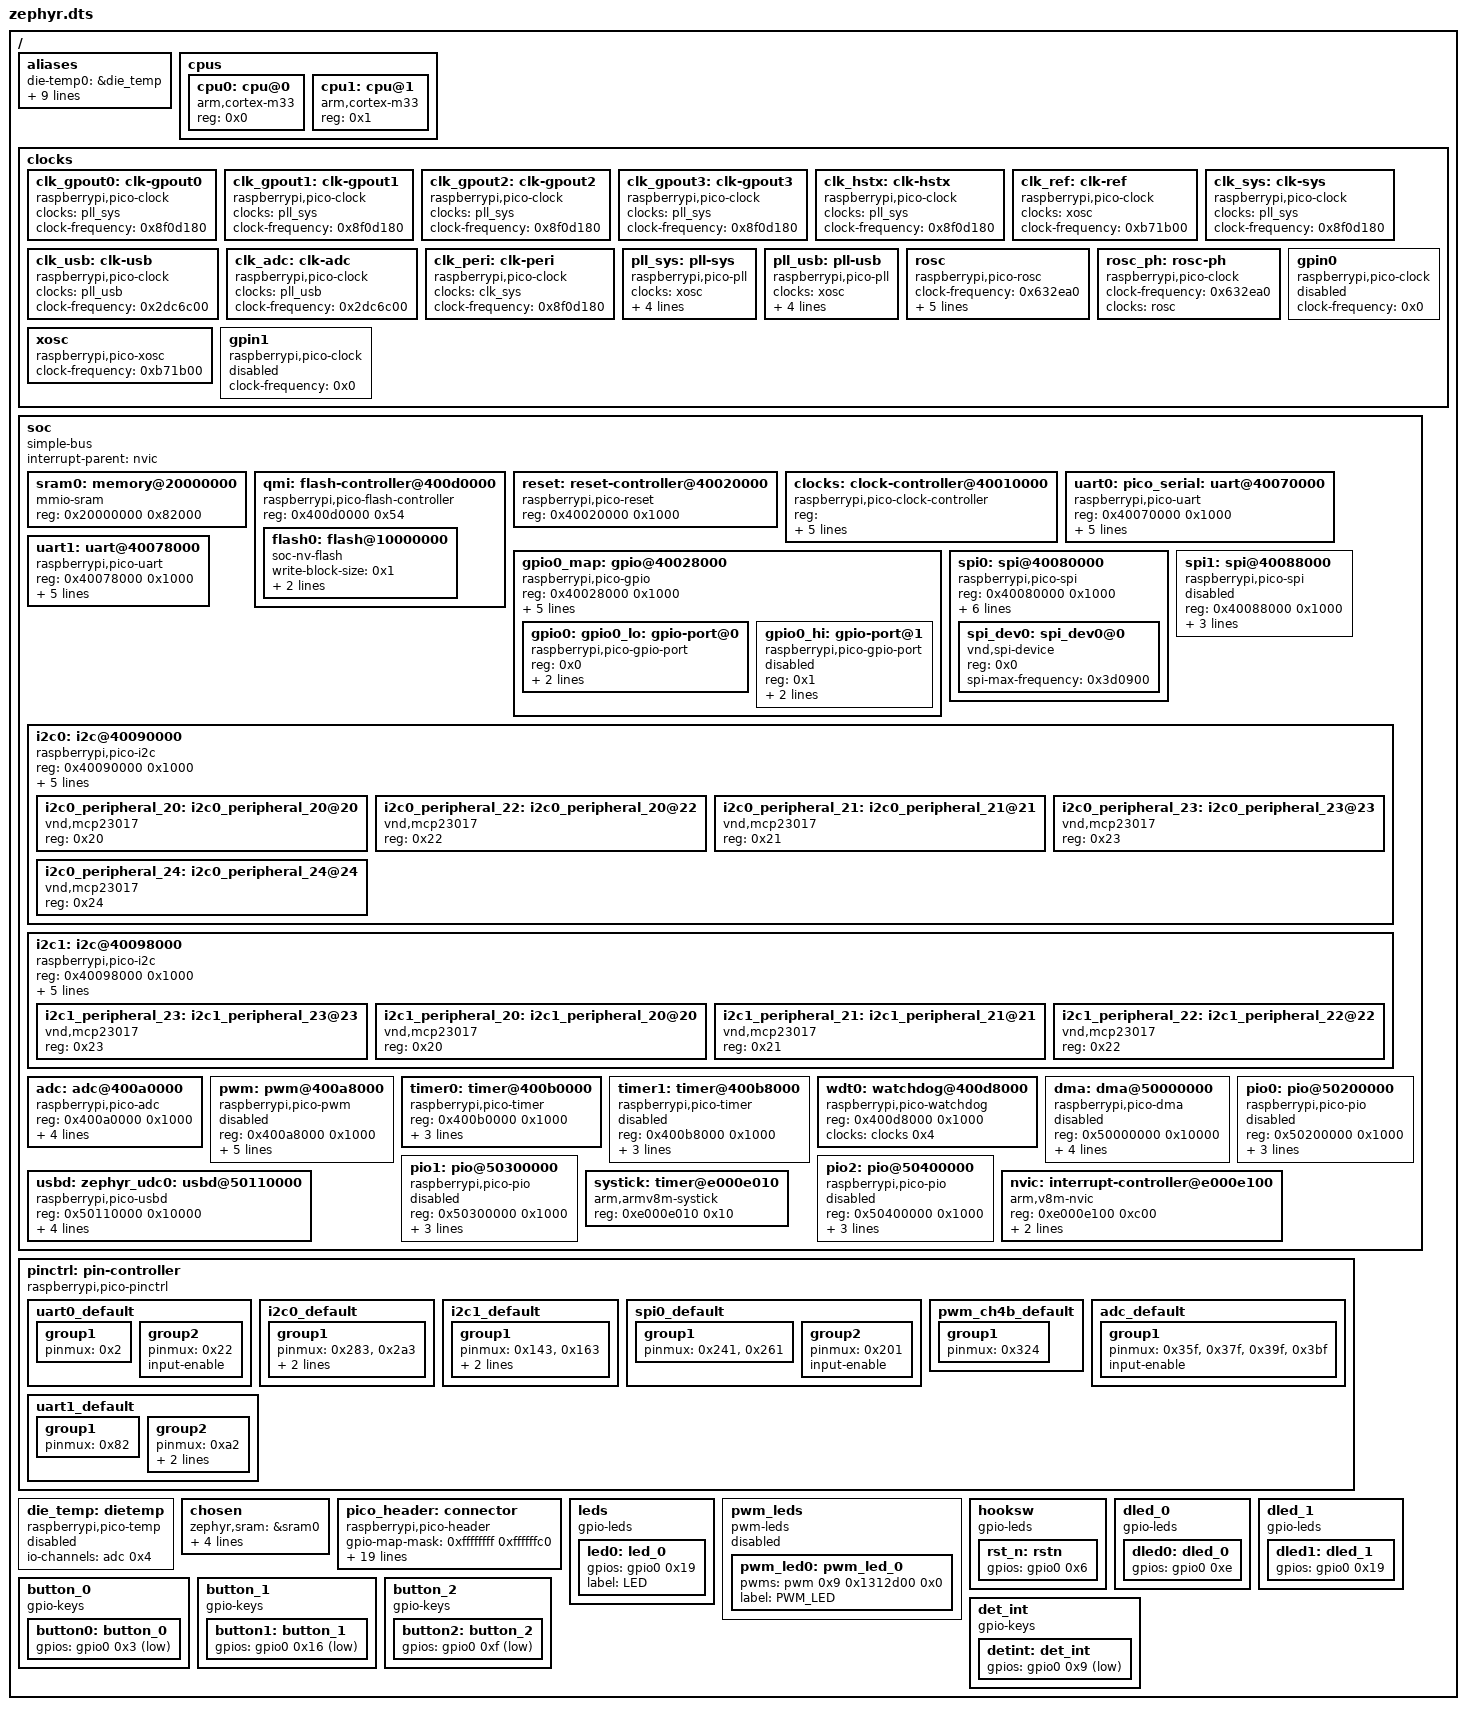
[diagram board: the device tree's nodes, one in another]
/dts-v1/;

/* node '/' defined in zephyr/dts/vendor/raspberrypi/rpi_pico/rp2350.dtsi:19 */
/ {
	#address-cells = < 0x1 >; /* in zephyr/dts/common/skeleton.dtsi:10 */
	#size-cells = < 0x1 >;    /* in zephyr/dts/common/skeleton.dtsi:11 */

	/* node '/aliases' defined in zephyr/dts/vendor/raspberrypi/rpi_pico/rp2350.dtsi:20 */
	aliases {
		die-temp0 = &die_temp; /* in zephyr/dts/vendor/raspberrypi/rpi_pico/rp2350.dtsi:21 */
		watchdog0 = &wdt0;     /* in zephyr/boards/raspberrypi/rpi_pico2/rpi_pico2.dtsi:24 */
		pwm-led0 = &pwm_led0;  /* in zephyr/boards/raspberrypi/common/rpi_pico-led.dtsi:30 */
		rstn = &rst_n;         /* in ../Documents/BLUELINE/blueline/code_blueline/boards/rpi_pico2_rp2350a_m33.overlay:183 */
		sw0 = &button0;        /* in ../Documents/BLUELINE/blueline/code_blueline/boards/rpi_pico2_rp2350a_m33.overlay:184 */
		sw1 = &button1;        /* in ../Documents/BLUELINE/blueline/code_blueline/boards/rpi_pico2_rp2350a_m33.overlay:185 */
		sw2 = &button2;        /* in ../Documents/BLUELINE/blueline/code_blueline/boards/rpi_pico2_rp2350a_m33.overlay:186 */
		detint = &detint;      /* in ../Documents/BLUELINE/blueline/code_blueline/boards/rpi_pico2_rp2350a_m33.overlay:187 */
		led0 = &dled0;         /* in ../Documents/BLUELINE/blueline/code_blueline/boards/rpi_pico2_rp2350a_m33.overlay:188 */
		led1 = &dled1;         /* in ../Documents/BLUELINE/blueline/code_blueline/boards/rpi_pico2_rp2350a_m33.overlay:189 */
	};

	/* node '/cpus' defined in zephyr/dts/vendor/raspberrypi/rpi_pico/rp2350.dtsi:24 */
	cpus {
		#address-cells = < 0x1 >; /* in zephyr/dts/vendor/raspberrypi/rpi_pico/rp2350.dtsi:25 */
		#size-cells = < 0x0 >;    /* in zephyr/dts/vendor/raspberrypi/rpi_pico/rp2350.dtsi:26 */

		/* node '/cpus/cpu@0' defined in zephyr/dts/vendor/raspberrypi/rpi_pico/rp2350.dtsi:33 */
		cpu0: cpu@0 {
			reg = < 0x0 >;                 /* in zephyr/dts/vendor/raspberrypi/rpi_pico/rp2350.dtsi:34 */
			compatible = "arm,cortex-m33"; /* in zephyr/dts/arm/raspberrypi/rpi_pico/m33.dtsi:13 */
		};

		/* node '/cpus/cpu@1' defined in zephyr/dts/vendor/raspberrypi/rpi_pico/rp2350.dtsi:37 */
		cpu1: cpu@1 {
			reg = < 0x1 >;                 /* in zephyr/dts/vendor/raspberrypi/rpi_pico/rp2350.dtsi:38 */
			compatible = "arm,cortex-m33"; /* in zephyr/dts/arm/raspberrypi/rpi_pico/m33.dtsi:17 */
		};
	};

	/* node '/clocks' defined in zephyr/dts/vendor/raspberrypi/rpi_pico/rp2350.dtsi:42 */
	clocks {

		/* node '/clocks/clk-gpout0' defined in zephyr/dts/vendor/raspberrypi/rpi_pico/rp2350.dtsi:43 */
		clk_gpout0: clk-gpout0 {
			compatible = "raspberrypi,pico-clock"; /* in zephyr/dts/vendor/raspberrypi/rpi_pico/rp2350.dtsi:44 */
			clocks = < &pll_sys >;                 /* in zephyr/dts/vendor/raspberrypi/rpi_pico/rp2350.dtsi:45 */
			clock-names = "pll_sys";               /* in zephyr/dts/vendor/raspberrypi/rpi_pico/rp2350.dtsi:46 */
			clock-frequency = < 0x8f0d180 >;       /* in zephyr/dts/vendor/raspberrypi/rpi_pico/rp2350.dtsi:47 */
			#clock-cells = < 0x0 >;                /* in zephyr/dts/vendor/raspberrypi/rpi_pico/rp2350.dtsi:48 */
			#address-cells = < 0x0 >;              /* in zephyr/dts/vendor/raspberrypi/rpi_pico/rp2350.dtsi:49 */
			phandle = < 0x7 >;                     /* in zephyr/dts/vendor/raspberrypi/rpi_pico/rp2350.dtsi:223 */
		};

		/* node '/clocks/clk-gpout1' defined in zephyr/dts/vendor/raspberrypi/rpi_pico/rp2350.dtsi:52 */
		clk_gpout1: clk-gpout1 {
			compatible = "raspberrypi,pico-clock"; /* in zephyr/dts/vendor/raspberrypi/rpi_pico/rp2350.dtsi:53 */
			clocks = < &pll_sys >;                 /* in zephyr/dts/vendor/raspberrypi/rpi_pico/rp2350.dtsi:54 */
			clock-names = "pll_sys";               /* in zephyr/dts/vendor/raspberrypi/rpi_pico/rp2350.dtsi:55 */
			clock-frequency = < 0x8f0d180 >;       /* in zephyr/dts/vendor/raspberrypi/rpi_pico/rp2350.dtsi:56 */
			#clock-cells = < 0x0 >;                /* in zephyr/dts/vendor/raspberrypi/rpi_pico/rp2350.dtsi:57 */
			phandle = < 0x8 >;                     /* in zephyr/dts/vendor/raspberrypi/rpi_pico/rp2350.dtsi:223 */
		};

		/* node '/clocks/clk-gpout2' defined in zephyr/dts/vendor/raspberrypi/rpi_pico/rp2350.dtsi:60 */
		clk_gpout2: clk-gpout2 {
			compatible = "raspberrypi,pico-clock"; /* in zephyr/dts/vendor/raspberrypi/rpi_pico/rp2350.dtsi:61 */
			clocks = < &pll_sys >;                 /* in zephyr/dts/vendor/raspberrypi/rpi_pico/rp2350.dtsi:62 */
			clock-names = "pll_sys";               /* in zephyr/dts/vendor/raspberrypi/rpi_pico/rp2350.dtsi:63 */
			clock-frequency = < 0x8f0d180 >;       /* in zephyr/dts/vendor/raspberrypi/rpi_pico/rp2350.dtsi:64 */
			#clock-cells = < 0x0 >;                /* in zephyr/dts/vendor/raspberrypi/rpi_pico/rp2350.dtsi:65 */
			phandle = < 0x9 >;                     /* in zephyr/dts/vendor/raspberrypi/rpi_pico/rp2350.dtsi:223 */
		};

		/* node '/clocks/clk-gpout3' defined in zephyr/dts/vendor/raspberrypi/rpi_pico/rp2350.dtsi:68 */
		clk_gpout3: clk-gpout3 {
			compatible = "raspberrypi,pico-clock"; /* in zephyr/dts/vendor/raspberrypi/rpi_pico/rp2350.dtsi:69 */
			clocks = < &pll_sys >;                 /* in zephyr/dts/vendor/raspberrypi/rpi_pico/rp2350.dtsi:70 */
			clock-names = "pll_sys";               /* in zephyr/dts/vendor/raspberrypi/rpi_pico/rp2350.dtsi:71 */
			clock-frequency = < 0x8f0d180 >;       /* in zephyr/dts/vendor/raspberrypi/rpi_pico/rp2350.dtsi:72 */
			#clock-cells = < 0x0 >;                /* in zephyr/dts/vendor/raspberrypi/rpi_pico/rp2350.dtsi:73 */
			phandle = < 0xa >;                     /* in zephyr/dts/vendor/raspberrypi/rpi_pico/rp2350.dtsi:223 */
		};

		/* node '/clocks/clk-hstx' defined in zephyr/dts/vendor/raspberrypi/rpi_pico/rp2350.dtsi:76 */
		clk_hstx: clk-hstx {
			compatible = "raspberrypi,pico-clock"; /* in zephyr/dts/vendor/raspberrypi/rpi_pico/rp2350.dtsi:77 */
			clocks = < &pll_sys >;                 /* in zephyr/dts/vendor/raspberrypi/rpi_pico/rp2350.dtsi:78 */
			clock-names = "pll_sys";               /* in zephyr/dts/vendor/raspberrypi/rpi_pico/rp2350.dtsi:79 */
			clock-frequency = < 0x8f0d180 >;       /* in zephyr/dts/vendor/raspberrypi/rpi_pico/rp2350.dtsi:80 */
			#clock-cells = < 0x0 >;                /* in zephyr/dts/vendor/raspberrypi/rpi_pico/rp2350.dtsi:81 */
			phandle = < 0xb >;                     /* in zephyr/dts/vendor/raspberrypi/rpi_pico/rp2350.dtsi:223 */
		};

		/* node '/clocks/clk-ref' defined in zephyr/dts/vendor/raspberrypi/rpi_pico/rp2350.dtsi:84 */
		clk_ref: clk-ref {
			compatible = "raspberrypi,pico-clock"; /* in zephyr/dts/vendor/raspberrypi/rpi_pico/rp2350.dtsi:85 */
			clocks = < &xosc >;                    /* in zephyr/dts/vendor/raspberrypi/rpi_pico/rp2350.dtsi:86 */
			clock-names = "xosc";                  /* in zephyr/dts/vendor/raspberrypi/rpi_pico/rp2350.dtsi:87 */
			clock-frequency = < 0xb71b00 >;        /* in zephyr/dts/vendor/raspberrypi/rpi_pico/rp2350.dtsi:88 */
			#clock-cells = < 0x0 >;                /* in zephyr/dts/vendor/raspberrypi/rpi_pico/rp2350.dtsi:89 */
			phandle = < 0xc >;                     /* in zephyr/dts/vendor/raspberrypi/rpi_pico/rp2350.dtsi:223 */
		};

		/* node '/clocks/clk-sys' defined in zephyr/dts/vendor/raspberrypi/rpi_pico/rp2350.dtsi:92 */
		clk_sys: clk-sys {
			compatible = "raspberrypi,pico-clock"; /* in zephyr/dts/vendor/raspberrypi/rpi_pico/rp2350.dtsi:93 */
			clocks = < &pll_sys >;                 /* in zephyr/dts/vendor/raspberrypi/rpi_pico/rp2350.dtsi:94 */
			clock-names = "pll_sys";               /* in zephyr/dts/vendor/raspberrypi/rpi_pico/rp2350.dtsi:95 */
			clock-frequency = < 0x8f0d180 >;       /* in zephyr/dts/vendor/raspberrypi/rpi_pico/rp2350.dtsi:96 */
			#clock-cells = < 0x0 >;                /* in zephyr/dts/vendor/raspberrypi/rpi_pico/rp2350.dtsi:97 */
			phandle = < 0x4 >;                     /* in zephyr/dts/vendor/raspberrypi/rpi_pico/rp2350.dtsi:118 */
		};

		/* node '/clocks/clk-usb' defined in zephyr/dts/vendor/raspberrypi/rpi_pico/rp2350.dtsi:100 */
		clk_usb: clk-usb {
			compatible = "raspberrypi,pico-clock"; /* in zephyr/dts/vendor/raspberrypi/rpi_pico/rp2350.dtsi:101 */
			clocks = < &pll_usb >;                 /* in zephyr/dts/vendor/raspberrypi/rpi_pico/rp2350.dtsi:102 */
			clock-names = "pll_usb";               /* in zephyr/dts/vendor/raspberrypi/rpi_pico/rp2350.dtsi:103 */
			clock-frequency = < 0x2dc6c00 >;       /* in zephyr/dts/vendor/raspberrypi/rpi_pico/rp2350.dtsi:104 */
			#clock-cells = < 0x0 >;                /* in zephyr/dts/vendor/raspberrypi/rpi_pico/rp2350.dtsi:105 */
			phandle = < 0xe >;                     /* in zephyr/dts/vendor/raspberrypi/rpi_pico/rp2350.dtsi:223 */
		};

		/* node '/clocks/clk-adc' defined in zephyr/dts/vendor/raspberrypi/rpi_pico/rp2350.dtsi:108 */
		clk_adc: clk-adc {
			compatible = "raspberrypi,pico-clock"; /* in zephyr/dts/vendor/raspberrypi/rpi_pico/rp2350.dtsi:109 */
			clocks = < &pll_usb >;                 /* in zephyr/dts/vendor/raspberrypi/rpi_pico/rp2350.dtsi:110 */
			clock-names = "pll_usb";               /* in zephyr/dts/vendor/raspberrypi/rpi_pico/rp2350.dtsi:111 */
			clock-frequency = < 0x2dc6c00 >;       /* in zephyr/dts/vendor/raspberrypi/rpi_pico/rp2350.dtsi:112 */
			#clock-cells = < 0x0 >;                /* in zephyr/dts/vendor/raspberrypi/rpi_pico/rp2350.dtsi:113 */
			phandle = < 0xf >;                     /* in zephyr/dts/vendor/raspberrypi/rpi_pico/rp2350.dtsi:223 */
		};

		/* node '/clocks/clk-peri' defined in zephyr/dts/vendor/raspberrypi/rpi_pico/rp2350.dtsi:116 */
		clk_peri: clk-peri {
			compatible = "raspberrypi,pico-clock"; /* in zephyr/dts/vendor/raspberrypi/rpi_pico/rp2350.dtsi:117 */
			clocks = < &clk_sys >;                 /* in zephyr/dts/vendor/raspberrypi/rpi_pico/rp2350.dtsi:118 */
			clock-names = "clk_sys";               /* in zephyr/dts/vendor/raspberrypi/rpi_pico/rp2350.dtsi:119 */
			clock-frequency = < 0x8f0d180 >;       /* in zephyr/dts/vendor/raspberrypi/rpi_pico/rp2350.dtsi:120 */
			#clock-cells = < 0x0 >;                /* in zephyr/dts/vendor/raspberrypi/rpi_pico/rp2350.dtsi:121 */
			phandle = < 0xd >;                     /* in zephyr/dts/vendor/raspberrypi/rpi_pico/rp2350.dtsi:223 */
		};

		/* node '/clocks/pll-sys' defined in zephyr/dts/vendor/raspberrypi/rpi_pico/rp2350.dtsi:124 */
		pll_sys: pll-sys {
			compatible = "raspberrypi,pico-pll"; /* in zephyr/dts/vendor/raspberrypi/rpi_pico/rp2350.dtsi:125 */
			clocks = < &xosc >;                  /* in zephyr/dts/vendor/raspberrypi/rpi_pico/rp2350.dtsi:126 */
			clock-names = "xosc";                /* in zephyr/dts/vendor/raspberrypi/rpi_pico/rp2350.dtsi:127 */
			clock-div = < 0x1 >;                 /* in zephyr/dts/vendor/raspberrypi/rpi_pico/rp2350.dtsi:128 */
			fb-div = < 0x7d >;                   /* in zephyr/dts/vendor/raspberrypi/rpi_pico/rp2350.dtsi:129 */
			post-div1 = < 0x5 >;                 /* in zephyr/dts/vendor/raspberrypi/rpi_pico/rp2350.dtsi:130 */
			post-div2 = < 0x2 >;                 /* in zephyr/dts/vendor/raspberrypi/rpi_pico/rp2350.dtsi:131 */
			#clock-cells = < 0x0 >;              /* in zephyr/dts/vendor/raspberrypi/rpi_pico/rp2350.dtsi:132 */
			phandle = < 0x1 >;                   /* in zephyr/dts/vendor/raspberrypi/rpi_pico/rp2350.dtsi:45 */
		};

		/* node '/clocks/pll-usb' defined in zephyr/dts/vendor/raspberrypi/rpi_pico/rp2350.dtsi:135 */
		pll_usb: pll-usb {
			compatible = "raspberrypi,pico-pll"; /* in zephyr/dts/vendor/raspberrypi/rpi_pico/rp2350.dtsi:136 */
			clocks = < &xosc >;                  /* in zephyr/dts/vendor/raspberrypi/rpi_pico/rp2350.dtsi:137 */
			clock-names = "xosc";                /* in zephyr/dts/vendor/raspberrypi/rpi_pico/rp2350.dtsi:138 */
			clock-div = < 0x1 >;                 /* in zephyr/dts/vendor/raspberrypi/rpi_pico/rp2350.dtsi:139 */
			fb-div = < 0x64 >;                   /* in zephyr/dts/vendor/raspberrypi/rpi_pico/rp2350.dtsi:140 */
			post-div1 = < 0x5 >;                 /* in zephyr/dts/vendor/raspberrypi/rpi_pico/rp2350.dtsi:141 */
			post-div2 = < 0x5 >;                 /* in zephyr/dts/vendor/raspberrypi/rpi_pico/rp2350.dtsi:142 */
			#clock-cells = < 0x0 >;              /* in zephyr/dts/vendor/raspberrypi/rpi_pico/rp2350.dtsi:143 */
			phandle = < 0x3 >;                   /* in zephyr/dts/vendor/raspberrypi/rpi_pico/rp2350.dtsi:102 */
		};

		/* node '/clocks/rosc' defined in zephyr/dts/vendor/raspberrypi/rpi_pico/rp2350.dtsi:146 */
		rosc: rosc {
			compatible = "raspberrypi,pico-rosc"; /* in zephyr/dts/vendor/raspberrypi/rpi_pico/rp2350.dtsi:147 */
			clock-frequency = < 0x632ea0 >;       /* in zephyr/dts/vendor/raspberrypi/rpi_pico/rp2350.dtsi:148 */
			range = < 0xaa0 >;                    /* in zephyr/dts/vendor/raspberrypi/rpi_pico/rp2350.dtsi:149 */
			stage-drive-strength = < 0x0 >,
			                       < 0x0 >,
			                       < 0x0 >,
			                       < 0x0 >,
			                       < 0x0 >,
			                       < 0x0 >,
			                       < 0x0 >,
			                       < 0x0 >;       /* in zephyr/dts/vendor/raspberrypi/rpi_pico/rp2350.dtsi:150 */
			clock-div = < 0x10 >;                 /* in zephyr/dts/vendor/raspberrypi/rpi_pico/rp2350.dtsi:151 */
			phase = < 0x0 >;                      /* in zephyr/dts/vendor/raspberrypi/rpi_pico/rp2350.dtsi:152 */
			#clock-cells = < 0x0 >;               /* in zephyr/dts/vendor/raspberrypi/rpi_pico/rp2350.dtsi:153 */
			phandle = < 0x5 >;                    /* in zephyr/dts/vendor/raspberrypi/rpi_pico/rp2350.dtsi:159 */
		};

		/* node '/clocks/rosc-ph' defined in zephyr/dts/vendor/raspberrypi/rpi_pico/rp2350.dtsi:156 */
		rosc_ph: rosc-ph {
			compatible = "raspberrypi,pico-clock"; /* in zephyr/dts/vendor/raspberrypi/rpi_pico/rp2350.dtsi:157 */
			clock-frequency = < 0x632ea0 >;        /* in zephyr/dts/vendor/raspberrypi/rpi_pico/rp2350.dtsi:158 */
			clocks = < &rosc >;                    /* in zephyr/dts/vendor/raspberrypi/rpi_pico/rp2350.dtsi:159 */
			clock-names = "rosc";                  /* in zephyr/dts/vendor/raspberrypi/rpi_pico/rp2350.dtsi:160 */
			#clock-cells = < 0x0 >;                /* in zephyr/dts/vendor/raspberrypi/rpi_pico/rp2350.dtsi:161 */
			phandle = < 0x10 >;                    /* in zephyr/dts/vendor/raspberrypi/rpi_pico/rp2350.dtsi:223 */
		};

		/* node '/clocks/xosc' defined in zephyr/dts/vendor/raspberrypi/rpi_pico/rp2350.dtsi:164 */
		xosc: xosc {
			compatible = "raspberrypi,pico-xosc"; /* in zephyr/dts/vendor/raspberrypi/rpi_pico/rp2350.dtsi:165 */
			clock-frequency = < 0xb71b00 >;       /* in zephyr/dts/vendor/raspberrypi/rpi_pico/rp2350.dtsi:166 */
			#clock-cells = < 0x0 >;               /* in zephyr/dts/vendor/raspberrypi/rpi_pico/rp2350.dtsi:167 */
			phandle = < 0x2 >;                    /* in zephyr/dts/vendor/raspberrypi/rpi_pico/rp2350.dtsi:86 */
		};

		/* node '/clocks/gpin0' defined in zephyr/dts/vendor/raspberrypi/rpi_pico/rp2350.dtsi:170 */
		gpin0: gpin0 {
			compatible = "raspberrypi,pico-clock"; /* in zephyr/dts/vendor/raspberrypi/rpi_pico/rp2350.dtsi:171 */
			status = "disabled";                   /* in zephyr/dts/vendor/raspberrypi/rpi_pico/rp2350.dtsi:172 */
			clock-frequency = < 0x0 >;             /* in zephyr/dts/vendor/raspberrypi/rpi_pico/rp2350.dtsi:173 */
			#clock-cells = < 0x0 >;                /* in zephyr/dts/vendor/raspberrypi/rpi_pico/rp2350.dtsi:174 */
			phandle = < 0x11 >;                    /* in zephyr/dts/vendor/raspberrypi/rpi_pico/rp2350.dtsi:223 */
		};

		/* node '/clocks/gpin1' defined in zephyr/dts/vendor/raspberrypi/rpi_pico/rp2350.dtsi:177 */
		gpin1: gpin1 {
			compatible = "raspberrypi,pico-clock"; /* in zephyr/dts/vendor/raspberrypi/rpi_pico/rp2350.dtsi:178 */
			status = "disabled";                   /* in zephyr/dts/vendor/raspberrypi/rpi_pico/rp2350.dtsi:179 */
			clock-frequency = < 0x0 >;             /* in zephyr/dts/vendor/raspberrypi/rpi_pico/rp2350.dtsi:180 */
			#clock-cells = < 0x0 >;                /* in zephyr/dts/vendor/raspberrypi/rpi_pico/rp2350.dtsi:181 */
			phandle = < 0x12 >;                    /* in zephyr/dts/vendor/raspberrypi/rpi_pico/rp2350.dtsi:223 */
		};
	};

	/* node '/soc' defined in zephyr/dts/vendor/raspberrypi/rpi_pico/rp2350.dtsi:185 */
	soc {
		#address-cells = < 0x1 >;     /* in zephyr/dts/arm/armv8-m.dtsi:7 */
		#size-cells = < 0x1 >;        /* in zephyr/dts/arm/armv8-m.dtsi:8 */
		compatible = "simple-bus";    /* in zephyr/dts/arm/armv8-m.dtsi:9 */
		interrupt-parent = < &nvic >; /* in zephyr/dts/arm/armv8-m.dtsi:10 */
		ranges;                       /* in zephyr/dts/arm/armv8-m.dtsi:11 */

		/* node '/soc/memory@20000000' defined in zephyr/dts/vendor/raspberrypi/rpi_pico/rp2350.dtsi:188 */
		sram0: memory@20000000 {
			compatible = "mmio-sram";     /* in zephyr/dts/vendor/raspberrypi/rpi_pico/rp2350.dtsi:189 */
			reg = < 0x20000000 0x82000 >; /* in zephyr/dts/vendor/raspberrypi/rpi_pico/rp2350.dtsi:190 */
		};

		/* node '/soc/flash-controller@400d0000' defined in zephyr/dts/vendor/raspberrypi/rpi_pico/rp2350.dtsi:193 */
		qmi: flash-controller@400d0000 {
			compatible = "raspberrypi,pico-flash-controller"; /* in zephyr/dts/vendor/raspberrypi/rpi_pico/rp2350.dtsi:194 */
			reg = < 0x400d0000 0x54 >;                        /* in zephyr/dts/vendor/raspberrypi/rpi_pico/rp2350.dtsi:195 */
			#address-cells = < 0x1 >;                         /* in zephyr/dts/vendor/raspberrypi/rpi_pico/rp2350.dtsi:197 */
			#size-cells = < 0x1 >;                            /* in zephyr/dts/vendor/raspberrypi/rpi_pico/rp2350.dtsi:198 */

			/* node '/soc/flash-controller@400d0000/flash@10000000' defined in zephyr/dts/vendor/raspberrypi/rpi_pico/rp2350.dtsi:200 */
			flash0: flash@10000000 {
				compatible = "soc-nv-flash";   /* in zephyr/dts/vendor/raspberrypi/rpi_pico/rp2350.dtsi:201 */
				write-block-size = < 0x1 >;    /* in zephyr/dts/vendor/raspberrypi/rpi_pico/rp2350.dtsi:202 */
				erase-block-size = < 0x1000 >; /* in zephyr/dts/vendor/raspberrypi/rpi_pico/rp2350.dtsi:203 */
				reg = < 0x10000000 0x400000 >; /* in zephyr/boards/raspberrypi/rpi_pico2/rpi_pico2.dtsi:62 */
			};
		};

		/* node '/soc/reset-controller@40020000' defined in zephyr/dts/vendor/raspberrypi/rpi_pico/rp2350.dtsi:207 */
		reset: reset-controller@40020000 {
			compatible = "raspberrypi,pico-reset"; /* in zephyr/dts/vendor/raspberrypi/rpi_pico/rp2350.dtsi:208 */
			reg = < 0x40020000 0x1000 >;           /* in zephyr/dts/vendor/raspberrypi/rpi_pico/rp2350.dtsi:209 */
			#reset-cells = < 0x1 >;                /* in zephyr/dts/vendor/raspberrypi/rpi_pico/rp2350.dtsi:210 */
			phandle = < 0x16 >;                    /* in zephyr/dts/vendor/raspberrypi/rpi_pico/rp2350.dtsi:271 */
		};

		/* node '/soc/clock-controller@40010000' defined in zephyr/dts/vendor/raspberrypi/rpi_pico/rp2350.dtsi:213 */
		clocks: clock-controller@40010000 {
			compatible = "raspberrypi,pico-clock-controller";                                          /* in zephyr/dts/vendor/raspberrypi/rpi_pico/rp2350.dtsi:214 */
			reg = < 0x40010000 0x1000 0x40048000 0x1000 0x40050000 0x1000 0x40058000 0x1000 0x400e8000
			        0x1000 >;                                                                          /* in zephyr/dts/vendor/raspberrypi/rpi_pico/rp2350.dtsi:215 */
			reg-names = "clocks",
			            "xosc",
			            "pll_sys",
			            "pll_usb",
			            "rosc";                                                                        /* in zephyr/dts/vendor/raspberrypi/rpi_pico/rp2350.dtsi:220 */
			#clock-cells = < 0x1 >;                                                                    /* in zephyr/dts/vendor/raspberrypi/rpi_pico/rp2350.dtsi:221 */
			status = "okay";                                                                           /* in zephyr/dts/vendor/raspberrypi/rpi_pico/rp2350.dtsi:222 */
			clocks = < &clk_gpout0 >,
			         < &clk_gpout1 >,
			         < &clk_gpout2 >,
			         < &clk_gpout3 >,
			         < &clk_hstx >,
			         < &clk_ref >,
			         < &clk_sys >,
			         < &clk_peri >,
			         < &clk_usb >,
			         < &clk_adc >,
			         < &pll_sys >,
			         < &pll_usb >,
			         < &xosc >,
			         < &rosc >,
			         < &rosc_ph >,
			         < &gpin0 >,
			         < &gpin1 >;                                                                       /* in zephyr/dts/vendor/raspberrypi/rpi_pico/rp2350.dtsi:223 */
			clock-names = "clk_gpout0",
			              "clk_gpout1",
			              "clk_gpout2",
			              "clk_gpout3",
			              "clk_hstx",
			              "clk_ref",
			              "clk_sys",
			              "clk_peri",
			              "clk_usb",
			              "clk_adc",
			              "pll_sys",
			              "pll_usb",
			              "xosc",
			              "rosc",
			              "rosc_ph",
			              "gpin0",
			              "gpin1";                                                                     /* in zephyr/dts/vendor/raspberrypi/rpi_pico/rp2350.dtsi:228 */
			phandle = < 0x15 >;                                                                        /* in zephyr/dts/vendor/raspberrypi/rpi_pico/rp2350.dtsi:270 */
		};

		/* node '/soc/gpio@40028000' defined in zephyr/dts/vendor/raspberrypi/rpi_pico/rp2350.dtsi:235 */
		gpio0_map: gpio@40028000 {
			compatible = "raspberrypi,pico-gpio";                             /* in zephyr/dts/vendor/raspberrypi/rpi_pico/rp2350.dtsi:236 */
			reg = < 0x40028000 0x1000 >;                                      /* in zephyr/dts/vendor/raspberrypi/rpi_pico/rp2350.dtsi:237 */
			interrupts = < 0x15 0x7 >;                                        /* in zephyr/dts/vendor/raspberrypi/rpi_pico/rp2350.dtsi:238 */
			gpio-map-mask = < 0xffffffe0 0xffffffc0 >;                        /* in zephyr/dts/vendor/raspberrypi/rpi_pico/rp2350.dtsi:240 */
			gpio-map-pass-thru = < 0x1f 0x3f >;                               /* in zephyr/dts/vendor/raspberrypi/rpi_pico/rp2350.dtsi:241 */
			gpio-map = < 0x0 0x0 &gpio0 0x0 0x0 0x20 0x0 &gpio0_hi 0x0 0x0 >; /* in zephyr/dts/vendor/raspberrypi/rpi_pico/rp2350.dtsi:242 */
			#gpio-cells = < 0x2 >;                                            /* in zephyr/dts/vendor/raspberrypi/rpi_pico/rp2350.dtsi:244 */
			#address-cells = < 0x1 >;                                         /* in zephyr/dts/vendor/raspberrypi/rpi_pico/rp2350.dtsi:245 */
			#size-cells = < 0x0 >;                                            /* in zephyr/dts/vendor/raspberrypi/rpi_pico/rp2350.dtsi:246 */

			/* node '/soc/gpio@40028000/gpio-port@0' defined in zephyr/dts/vendor/raspberrypi/rpi_pico/rp2350.dtsi:248 */
			gpio0: gpio0_lo: gpio-port@0 {
				compatible = "raspberrypi,pico-gpio-port"; /* in zephyr/dts/vendor/raspberrypi/rpi_pico/rp2350.dtsi:249 */
				reg = < 0x0 >;                             /* in zephyr/dts/vendor/raspberrypi/rpi_pico/rp2350.dtsi:250 */
				gpio-controller;                           /* in zephyr/dts/vendor/raspberrypi/rpi_pico/rp2350.dtsi:252 */
				#gpio-cells = < 0x2 >;                     /* in zephyr/dts/vendor/raspberrypi/rpi_pico/rp2350.dtsi:253 */
				ngpios = < 0x1e >;                         /* in zephyr/dts/vendor/raspberrypi/rpi_pico/rp2350a.dtsi:4 */
				status = "okay";                           /* in zephyr/boards/raspberrypi/rpi_pico2/rpi_pico2.dtsi:73 */
				phandle = < 0x13 >;                        /* in zephyr/dts/vendor/raspberrypi/rpi_pico/rp2350.dtsi:242 */
			};

			/* node '/soc/gpio@40028000/gpio-port@1' defined in zephyr/dts/vendor/raspberrypi/rpi_pico/rp2350.dtsi:257 */
			gpio0_hi: gpio-port@1 {
				compatible = "raspberrypi,pico-gpio-port"; /* in zephyr/dts/vendor/raspberrypi/rpi_pico/rp2350.dtsi:258 */
				reg = < 0x1 >;                             /* in zephyr/dts/vendor/raspberrypi/rpi_pico/rp2350.dtsi:259 */
				status = "disabled";                       /* in zephyr/dts/vendor/raspberrypi/rpi_pico/rp2350.dtsi:260 */
				gpio-controller;                           /* in zephyr/dts/vendor/raspberrypi/rpi_pico/rp2350.dtsi:261 */
				#gpio-cells = < 0x2 >;                     /* in zephyr/dts/vendor/raspberrypi/rpi_pico/rp2350.dtsi:262 */
				ngpios = < 0x20 >;                         /* in zephyr/dts/vendor/raspberrypi/rpi_pico/rp2350.dtsi:263 */
				phandle = < 0x14 >;                        /* in zephyr/dts/vendor/raspberrypi/rpi_pico/rp2350.dtsi:242 */
			};
		};

		/* node '/soc/uart@40070000' defined in zephyr/dts/vendor/raspberrypi/rpi_pico/rp2350.dtsi:267 */
		uart0: pico_serial: uart@40070000 {
			compatible = "raspberrypi,pico-uart",
			             "arm,pl011";             /* in zephyr/dts/vendor/raspberrypi/rpi_pico/rp2350.dtsi:268 */
			reg = < 0x40070000 0x1000 >;          /* in zephyr/dts/vendor/raspberrypi/rpi_pico/rp2350.dtsi:269 */
			clocks = < &clocks 0x6 >;             /* in zephyr/dts/vendor/raspberrypi/rpi_pico/rp2350.dtsi:270 */
			resets = < &reset 0x1a >;             /* in zephyr/dts/vendor/raspberrypi/rpi_pico/rp2350.dtsi:271 */
			interrupts = < 0x21 0x7 >;            /* in zephyr/dts/vendor/raspberrypi/rpi_pico/rp2350.dtsi:272 */
			interrupt-names = "uart0";            /* in zephyr/dts/vendor/raspberrypi/rpi_pico/rp2350.dtsi:273 */
			current-speed = < 0x1c200 >;          /* in zephyr/boards/raspberrypi/rpi_pico2/rpi_pico2.dtsi:66 */
			status = "okay";                      /* in zephyr/boards/raspberrypi/rpi_pico2/rpi_pico2.dtsi:67 */
			pinctrl-0 = < &uart0_default >;       /* in zephyr/boards/raspberrypi/rpi_pico2/rpi_pico2.dtsi:68 */
			pinctrl-names = "default";            /* in zephyr/boards/raspberrypi/rpi_pico2/rpi_pico2.dtsi:69 */
		};

		/* node '/soc/uart@40078000' defined in zephyr/dts/vendor/raspberrypi/rpi_pico/rp2350.dtsi:277 */
		uart1: uart@40078000 {
			compatible = "raspberrypi,pico-uart",
			             "arm,pl011";             /* in zephyr/dts/vendor/raspberrypi/rpi_pico/rp2350.dtsi:278 */
			reg = < 0x40078000 0x1000 >;          /* in zephyr/dts/vendor/raspberrypi/rpi_pico/rp2350.dtsi:279 */
			clocks = < &clocks 0x6 >;             /* in zephyr/dts/vendor/raspberrypi/rpi_pico/rp2350.dtsi:280 */
			resets = < &reset 0x1b >;             /* in zephyr/dts/vendor/raspberrypi/rpi_pico/rp2350.dtsi:281 */
			interrupts = < 0x22 0x7 >;            /* in zephyr/dts/vendor/raspberrypi/rpi_pico/rp2350.dtsi:282 */
			interrupt-names = "uart1";            /* in zephyr/dts/vendor/raspberrypi/rpi_pico/rp2350.dtsi:283 */
			status = "okay";                      /* in ../Documents/BLUELINE/blueline/code_blueline/boards/rpi_pico2_rp2350a_m33.overlay:46 */
			current-speed = < 0x1c200 >;          /* in ../Documents/BLUELINE/blueline/code_blueline/boards/rpi_pico2_rp2350a_m33.overlay:47 */
			pinctrl-0 = < &uart1_default >;       /* in ../Documents/BLUELINE/blueline/code_blueline/boards/rpi_pico2_rp2350a_m33.overlay:48 */
			pinctrl-names = "default";            /* in ../Documents/BLUELINE/blueline/code_blueline/boards/rpi_pico2_rp2350a_m33.overlay:49 */
		};

		/* node '/soc/spi@40080000' defined in zephyr/dts/vendor/raspberrypi/rpi_pico/rp2350.dtsi:287 */
		spi0: spi@40080000 {
			compatible = "raspberrypi,pico-spi",
			             "arm,pl022";            /* in zephyr/dts/vendor/raspberrypi/rpi_pico/rp2350.dtsi:288 */
			#address-cells = < 0x1 >;            /* in zephyr/dts/vendor/raspberrypi/rpi_pico/rp2350.dtsi:289 */
			#size-cells = < 0x0 >;               /* in zephyr/dts/vendor/raspberrypi/rpi_pico/rp2350.dtsi:290 */
			reg = < 0x40080000 0x1000 >;         /* in zephyr/dts/vendor/raspberrypi/rpi_pico/rp2350.dtsi:291 */
			clocks = < &clocks 0x6 >;            /* in zephyr/dts/vendor/raspberrypi/rpi_pico/rp2350.dtsi:292 */
			resets = < &reset 0x12 >;            /* in zephyr/dts/vendor/raspberrypi/rpi_pico/rp2350.dtsi:293 */
			interrupts = < 0x1f 0x7 >;           /* in zephyr/dts/vendor/raspberrypi/rpi_pico/rp2350.dtsi:294 */
			interrupt-names = "spi0";            /* in zephyr/dts/vendor/raspberrypi/rpi_pico/rp2350.dtsi:295 */
			clock-frequency = < 0x7a1200 >;      /* in zephyr/boards/raspberrypi/rpi_pico2/rpi_pico2.dtsi:77 */
			status = "okay";                     /* in ../Documents/BLUELINE/blueline/code_blueline/boards/rpi_pico2_rp2350a_m33.overlay:117 */
			pinctrl-0 = < &spi0_default >;       /* in ../Documents/BLUELINE/blueline/code_blueline/boards/rpi_pico2_rp2350a_m33.overlay:118 */
			pinctrl-names = "default";           /* in ../Documents/BLUELINE/blueline/code_blueline/boards/rpi_pico2_rp2350a_m33.overlay:119 */
			cs-gpios = < &gpio0 0x11 0x1 >;      /* in ../Documents/BLUELINE/blueline/code_blueline/boards/rpi_pico2_rp2350a_m33.overlay:120 */

			/* node '/soc/spi@40080000/spi_dev0@0' defined in ../Documents/BLUELINE/blueline/code_blueline/boards/rpi_pico2_rp2350a_m33.overlay:122 */
			spi_dev0: spi_dev0@0 {
				compatible = "vnd,spi-device";    /* in ../Documents/BLUELINE/blueline/code_blueline/boards/rpi_pico2_rp2350a_m33.overlay:123 */
				reg = < 0x0 >;                    /* in ../Documents/BLUELINE/blueline/code_blueline/boards/rpi_pico2_rp2350a_m33.overlay:124 */
				spi-max-frequency = < 0x3d0900 >; /* in ../Documents/BLUELINE/blueline/code_blueline/boards/rpi_pico2_rp2350a_m33.overlay:125 */
			};
		};

		/* node '/soc/spi@40088000' defined in zephyr/dts/vendor/raspberrypi/rpi_pico/rp2350.dtsi:299 */
		spi1: spi@40088000 {
			compatible = "raspberrypi,pico-spi",
			             "arm,pl022";            /* in zephyr/dts/vendor/raspberrypi/rpi_pico/rp2350.dtsi:300 */
			#address-cells = < 0x1 >;            /* in zephyr/dts/vendor/raspberrypi/rpi_pico/rp2350.dtsi:301 */
			#size-cells = < 0x0 >;               /* in zephyr/dts/vendor/raspberrypi/rpi_pico/rp2350.dtsi:302 */
			reg = < 0x40088000 0x1000 >;         /* in zephyr/dts/vendor/raspberrypi/rpi_pico/rp2350.dtsi:303 */
			resets = < &reset 0x13 >;            /* in zephyr/dts/vendor/raspberrypi/rpi_pico/rp2350.dtsi:304 */
			clocks = < &clocks 0x6 >;            /* in zephyr/dts/vendor/raspberrypi/rpi_pico/rp2350.dtsi:305 */
			interrupts = < 0x20 0x7 >;           /* in zephyr/dts/vendor/raspberrypi/rpi_pico/rp2350.dtsi:306 */
			interrupt-names = "spi1";            /* in zephyr/dts/vendor/raspberrypi/rpi_pico/rp2350.dtsi:307 */
			status = "disabled";                 /* in zephyr/dts/vendor/raspberrypi/rpi_pico/rp2350.dtsi:308 */
		};

		/* node '/soc/i2c@40090000' defined in zephyr/dts/vendor/raspberrypi/rpi_pico/rp2350.dtsi:311 */
		i2c0: i2c@40090000 {
			compatible = "raspberrypi,pico-i2c",
			             "snps,designware-i2c";  /* in zephyr/dts/vendor/raspberrypi/rpi_pico/rp2350.dtsi:312 */
			#address-cells = < 0x1 >;            /* in zephyr/dts/vendor/raspberrypi/rpi_pico/rp2350.dtsi:313 */
			#size-cells = < 0x0 >;               /* in zephyr/dts/vendor/raspberrypi/rpi_pico/rp2350.dtsi:314 */
			reg = < 0x40090000 0x1000 >;         /* in zephyr/dts/vendor/raspberrypi/rpi_pico/rp2350.dtsi:315 */
			resets = < &reset 0x4 >;             /* in zephyr/dts/vendor/raspberrypi/rpi_pico/rp2350.dtsi:316 */
			clocks = < &clocks 0x5 >;            /* in zephyr/dts/vendor/raspberrypi/rpi_pico/rp2350.dtsi:317 */
			interrupts = < 0x24 0x7 >;           /* in zephyr/dts/vendor/raspberrypi/rpi_pico/rp2350.dtsi:318 */
			interrupt-names = "i2c0";            /* in zephyr/dts/vendor/raspberrypi/rpi_pico/rp2350.dtsi:319 */
			status = "okay";                     /* in ../Documents/BLUELINE/blueline/code_blueline/boards/rpi_pico2_rp2350a_m33.overlay:82 */
			pinctrl-0 = < &i2c0_default >;       /* in ../Documents/BLUELINE/blueline/code_blueline/boards/rpi_pico2_rp2350a_m33.overlay:83 */
			pinctrl-names = "default";           /* in ../Documents/BLUELINE/blueline/code_blueline/boards/rpi_pico2_rp2350a_m33.overlay:84 */
			clock-frequency = < 0x186a0 >;       /* in ../Documents/BLUELINE/blueline/code_blueline/boards/rpi_pico2_rp2350a_m33.overlay:85 */

			/* node '/soc/i2c@40090000/i2c0_peripheral_20@20' defined in ../Documents/BLUELINE/blueline/code_blueline/boards/rpi_pico2_rp2350a_m33.overlay:87 */
			i2c0_peripheral_20: i2c0_peripheral_20@20 {
				compatible = "vnd,mcp23017"; /* in ../Documents/BLUELINE/blueline/code_blueline/boards/rpi_pico2_rp2350a_m33.overlay:88 */
				reg = < 0x20 >;              /* in ../Documents/BLUELINE/blueline/code_blueline/boards/rpi_pico2_rp2350a_m33.overlay:89 */
			};

			/* node '/soc/i2c@40090000/i2c0_peripheral_20@22' defined in ../Documents/BLUELINE/blueline/code_blueline/boards/rpi_pico2_rp2350a_m33.overlay:92 */
			i2c0_peripheral_22: i2c0_peripheral_20@22 {
				compatible = "vnd,mcp23017"; /* in ../Documents/BLUELINE/blueline/code_blueline/boards/rpi_pico2_rp2350a_m33.overlay:93 */
				reg = < 0x22 >;              /* in ../Documents/BLUELINE/blueline/code_blueline/boards/rpi_pico2_rp2350a_m33.overlay:94 */
			};

			/* node '/soc/i2c@40090000/i2c0_peripheral_21@21' defined in ../Documents/BLUELINE/blueline/code_blueline/boards/rpi_pico2_rp2350a_m33.overlay:97 */
			i2c0_peripheral_21: i2c0_peripheral_21@21 {
				compatible = "vnd,mcp23017"; /* in ../Documents/BLUELINE/blueline/code_blueline/boards/rpi_pico2_rp2350a_m33.overlay:98 */
				reg = < 0x21 >;              /* in ../Documents/BLUELINE/blueline/code_blueline/boards/rpi_pico2_rp2350a_m33.overlay:99 */
			};

			/* node '/soc/i2c@40090000/i2c0_peripheral_23@23' defined in ../Documents/BLUELINE/blueline/code_blueline/boards/rpi_pico2_rp2350a_m33.overlay:102 */
			i2c0_peripheral_23: i2c0_peripheral_23@23 {
				compatible = "vnd,mcp23017"; /* in ../Documents/BLUELINE/blueline/code_blueline/boards/rpi_pico2_rp2350a_m33.overlay:103 */
				reg = < 0x23 >;              /* in ../Documents/BLUELINE/blueline/code_blueline/boards/rpi_pico2_rp2350a_m33.overlay:104 */
			};

			/* node '/soc/i2c@40090000/i2c0_peripheral_24@24' defined in ../Documents/BLUELINE/blueline/code_blueline/boards/rpi_pico2_rp2350a_m33.overlay:107 */
			i2c0_peripheral_24: i2c0_peripheral_24@24 {
				compatible = "vnd,mcp23017"; /* in ../Documents/BLUELINE/blueline/code_blueline/boards/rpi_pico2_rp2350a_m33.overlay:108 */
				reg = < 0x24 >;              /* in ../Documents/BLUELINE/blueline/code_blueline/boards/rpi_pico2_rp2350a_m33.overlay:109 */
			};
		};

		/* node '/soc/i2c@40098000' defined in zephyr/dts/vendor/raspberrypi/rpi_pico/rp2350.dtsi:323 */
		i2c1: i2c@40098000 {
			compatible = "raspberrypi,pico-i2c",
			             "snps,designware-i2c";  /* in zephyr/dts/vendor/raspberrypi/rpi_pico/rp2350.dtsi:324 */
			#address-cells = < 0x1 >;            /* in zephyr/dts/vendor/raspberrypi/rpi_pico/rp2350.dtsi:325 */
			#size-cells = < 0x0 >;               /* in zephyr/dts/vendor/raspberrypi/rpi_pico/rp2350.dtsi:326 */
			reg = < 0x40098000 0x1000 >;         /* in zephyr/dts/vendor/raspberrypi/rpi_pico/rp2350.dtsi:327 */
			resets = < &reset 0x5 >;             /* in zephyr/dts/vendor/raspberrypi/rpi_pico/rp2350.dtsi:328 */
			clocks = < &clocks 0x5 >;            /* in zephyr/dts/vendor/raspberrypi/rpi_pico/rp2350.dtsi:329 */
			interrupts = < 0x25 0x7 >;           /* in zephyr/dts/vendor/raspberrypi/rpi_pico/rp2350.dtsi:330 */
			interrupt-names = "i2c1";            /* in zephyr/dts/vendor/raspberrypi/rpi_pico/rp2350.dtsi:331 */
			status = "okay";                     /* in ../Documents/BLUELINE/blueline/code_blueline/boards/rpi_pico2_rp2350a_m33.overlay:53 */
			pinctrl-0 = < &i2c1_default >;       /* in ../Documents/BLUELINE/blueline/code_blueline/boards/rpi_pico2_rp2350a_m33.overlay:54 */
			pinctrl-names = "default";           /* in ../Documents/BLUELINE/blueline/code_blueline/boards/rpi_pico2_rp2350a_m33.overlay:55 */
			clock-frequency = < 0x186a0 >;       /* in ../Documents/BLUELINE/blueline/code_blueline/boards/rpi_pico2_rp2350a_m33.overlay:56 */

			/* node '/soc/i2c@40098000/i2c1_peripheral_23@23' defined in ../Documents/BLUELINE/blueline/code_blueline/boards/rpi_pico2_rp2350a_m33.overlay:58 */
			i2c1_peripheral_23: i2c1_peripheral_23@23 {
				compatible = "vnd,mcp23017"; /* in ../Documents/BLUELINE/blueline/code_blueline/boards/rpi_pico2_rp2350a_m33.overlay:59 */
				reg = < 0x23 >;              /* in ../Documents/BLUELINE/blueline/code_blueline/boards/rpi_pico2_rp2350a_m33.overlay:60 */
			};

			/* node '/soc/i2c@40098000/i2c1_peripheral_20@20' defined in ../Documents/BLUELINE/blueline/code_blueline/boards/rpi_pico2_rp2350a_m33.overlay:63 */
			i2c1_peripheral_20: i2c1_peripheral_20@20 {
				compatible = "vnd,mcp23017"; /* in ../Documents/BLUELINE/blueline/code_blueline/boards/rpi_pico2_rp2350a_m33.overlay:64 */
				reg = < 0x20 >;              /* in ../Documents/BLUELINE/blueline/code_blueline/boards/rpi_pico2_rp2350a_m33.overlay:65 */
			};

			/* node '/soc/i2c@40098000/i2c1_peripheral_21@21' defined in ../Documents/BLUELINE/blueline/code_blueline/boards/rpi_pico2_rp2350a_m33.overlay:68 */
			i2c1_peripheral_21: i2c1_peripheral_21@21 {
				compatible = "vnd,mcp23017"; /* in ../Documents/BLUELINE/blueline/code_blueline/boards/rpi_pico2_rp2350a_m33.overlay:69 */
				reg = < 0x21 >;              /* in ../Documents/BLUELINE/blueline/code_blueline/boards/rpi_pico2_rp2350a_m33.overlay:70 */
			};

			/* node '/soc/i2c@40098000/i2c1_peripheral_22@22' defined in ../Documents/BLUELINE/blueline/code_blueline/boards/rpi_pico2_rp2350a_m33.overlay:73 */
			i2c1_peripheral_22: i2c1_peripheral_22@22 {
				compatible = "vnd,mcp23017"; /* in ../Documents/BLUELINE/blueline/code_blueline/boards/rpi_pico2_rp2350a_m33.overlay:74 */
				reg = < 0x22 >;              /* in ../Documents/BLUELINE/blueline/code_blueline/boards/rpi_pico2_rp2350a_m33.overlay:75 */
			};
		};

		/* node '/soc/adc@400a0000' defined in zephyr/dts/vendor/raspberrypi/rpi_pico/rp2350.dtsi:335 */
		adc: adc@400a0000 {
			compatible = "raspberrypi,pico-adc"; /* in zephyr/dts/vendor/raspberrypi/rpi_pico/rp2350.dtsi:336 */
			reg = < 0x400a0000 0x1000 >;         /* in zephyr/dts/vendor/raspberrypi/rpi_pico/rp2350.dtsi:337 */
			resets = < &reset 0x0 >;             /* in zephyr/dts/vendor/raspberrypi/rpi_pico/rp2350.dtsi:338 */
			clocks = < &clocks 0x9 >;            /* in zephyr/dts/vendor/raspberrypi/rpi_pico/rp2350.dtsi:339 */
			interrupts = < 0x23 0x7 >;           /* in zephyr/dts/vendor/raspberrypi/rpi_pico/rp2350.dtsi:340 */
			interrupt-names = "adc0";            /* in zephyr/dts/vendor/raspberrypi/rpi_pico/rp2350.dtsi:341 */
			#io-channel-cells = < 0x1 >;         /* in zephyr/dts/vendor/raspberrypi/rpi_pico/rp2350.dtsi:343 */
			pinctrl-0 = < &adc_default >;        /* in zephyr/boards/raspberrypi/rpi_pico2/rpi_pico2.dtsi:97 */
			pinctrl-names = "default";           /* in zephyr/boards/raspberrypi/rpi_pico2/rpi_pico2.dtsi:98 */
			status = "okay";                     /* in zephyr/boards/raspberrypi/rpi_pico2/rpi_pico2.dtsi:99 */
			phandle = < 0x1e >;                  /* in zephyr/dts/vendor/raspberrypi/rpi_pico/rp2350a.dtsi:8 */
		};

		/* node '/soc/pwm@400a8000' defined in zephyr/dts/vendor/raspberrypi/rpi_pico/rp2350.dtsi:346 */
		pwm: pwm@400a8000 {
			compatible = "raspberrypi,pico-pwm"; /* in zephyr/dts/vendor/raspberrypi/rpi_pico/rp2350.dtsi:347 */
			reg = < 0x400a8000 0x1000 >;         /* in zephyr/dts/vendor/raspberrypi/rpi_pico/rp2350.dtsi:348 */
			resets = < &reset 0x10 >;            /* in zephyr/dts/vendor/raspberrypi/rpi_pico/rp2350.dtsi:349 */
			clocks = < &clocks 0x5 >;            /* in zephyr/dts/vendor/raspberrypi/rpi_pico/rp2350.dtsi:350 */
			interrupts = < 0x8 0x7 >,
			             < 0x9 0x7 >;            /* in zephyr/dts/vendor/raspberrypi/rpi_pico/rp2350.dtsi:351 */
			interrupt-names = "PWM_IRQ_WRAP_0",
			                  "PWM_IRQ_WRAP_1";  /* in zephyr/dts/vendor/raspberrypi/rpi_pico/rp2350.dtsi:353 */
			status = "disabled";                 /* in zephyr/dts/vendor/raspberrypi/rpi_pico/rp2350.dtsi:355 */
			#pwm-cells = < 0x3 >;                /* in zephyr/dts/vendor/raspberrypi/rpi_pico/rp2350.dtsi:356 */
			pinctrl-0 = < &pwm_ch4b_default >;   /* in zephyr/boards/raspberrypi/rpi_pico2/rpi_pico2.dtsi:103 */
			pinctrl-names = "default";           /* in zephyr/boards/raspberrypi/rpi_pico2/rpi_pico2.dtsi:104 */
			divider-int-0 = < 0xff >;            /* in zephyr/boards/raspberrypi/rpi_pico2/rpi_pico2.dtsi:105 */
			phandle = < 0x1f >;                  /* in zephyr/boards/raspberrypi/common/rpi_pico-led.dtsi:23 */
		};

		/* node '/soc/timer@400b0000' defined in zephyr/dts/vendor/raspberrypi/rpi_pico/rp2350.dtsi:359 */
		timer0: timer@400b0000 {
			compatible = "raspberrypi,pico-timer"; /* in zephyr/dts/vendor/raspberrypi/rpi_pico/rp2350.dtsi:360 */
			reg = < 0x400b0000 0x1000 >;           /* in zephyr/dts/vendor/raspberrypi/rpi_pico/rp2350.dtsi:361 */
			resets = < &reset 0x17 >;              /* in zephyr/dts/vendor/raspberrypi/rpi_pico/rp2350.dtsi:362 */
			clocks = < &clocks 0x4 >;              /* in zephyr/dts/vendor/raspberrypi/rpi_pico/rp2350.dtsi:363 */
			interrupts = < 0x0 0x7 >,
			             < 0x1 0x7 >,
			             < 0x2 0x7 >,
			             < 0x3 0x7 >;              /* in zephyr/dts/vendor/raspberrypi/rpi_pico/rp2350.dtsi:364 */
			interrupt-names = "TIMER0_IRQ_0",
			                  "TIMER0_IRQ_1",
			                  "TIMER0_IRQ_2",
			                  "TIMER0_IRQ_3";      /* in zephyr/dts/vendor/raspberrypi/rpi_pico/rp2350.dtsi:368 */
			status = "okay";                       /* in zephyr/boards/raspberrypi/rpi_pico2/rpi_pico2.dtsi:109 */
		};

		/* node '/soc/timer@400b8000' defined in zephyr/dts/vendor/raspberrypi/rpi_pico/rp2350.dtsi:375 */
		timer1: timer@400b8000 {
			compatible = "raspberrypi,pico-timer"; /* in zephyr/dts/vendor/raspberrypi/rpi_pico/rp2350.dtsi:376 */
			reg = < 0x400b8000 0x1000 >;           /* in zephyr/dts/vendor/raspberrypi/rpi_pico/rp2350.dtsi:377 */
			resets = < &reset 0x18 >;              /* in zephyr/dts/vendor/raspberrypi/rpi_pico/rp2350.dtsi:378 */
			clocks = < &clocks 0x4 >;              /* in zephyr/dts/vendor/raspberrypi/rpi_pico/rp2350.dtsi:379 */
			interrupts = < 0x4 0x7 >,
			             < 0x5 0x7 >,
			             < 0x6 0x7 >,
			             < 0x7 0x7 >;              /* in zephyr/dts/vendor/raspberrypi/rpi_pico/rp2350.dtsi:380 */
			interrupt-names = "TIMER1_IRQ_0",
			                  "TIMER1_IRQ_1",
			                  "TIMER1_IRQ_2",
			                  "TIMER1_IRQ_3";      /* in zephyr/dts/vendor/raspberrypi/rpi_pico/rp2350.dtsi:384 */
			status = "disabled";                   /* in zephyr/dts/vendor/raspberrypi/rpi_pico/rp2350.dtsi:388 */
		};

		/* node '/soc/watchdog@400d8000' defined in zephyr/dts/vendor/raspberrypi/rpi_pico/rp2350.dtsi:391 */
		wdt0: watchdog@400d8000 {
			compatible = "raspberrypi,pico-watchdog"; /* in zephyr/dts/vendor/raspberrypi/rpi_pico/rp2350.dtsi:392 */
			reg = < 0x400d8000 0x1000 >;              /* in zephyr/dts/vendor/raspberrypi/rpi_pico/rp2350.dtsi:393 */
			clocks = < &clocks 0x4 >;                 /* in zephyr/dts/vendor/raspberrypi/rpi_pico/rp2350.dtsi:394 */
			status = "okay";                          /* in zephyr/boards/raspberrypi/rpi_pico2/rpi_pico2.dtsi:113 */
		};

		/* node '/soc/dma@50000000' defined in zephyr/dts/vendor/raspberrypi/rpi_pico/rp2350.dtsi:398 */
		dma: dma@50000000 {
			compatible = "raspberrypi,pico-dma"; /* in zephyr/dts/vendor/raspberrypi/rpi_pico/rp2350.dtsi:399 */
			reg = < 0x50000000 0x10000 >;        /* in zephyr/dts/vendor/raspberrypi/rpi_pico/rp2350.dtsi:400 */
			resets = < &reset 0x2 >;             /* in zephyr/dts/vendor/raspberrypi/rpi_pico/rp2350.dtsi:401 */
			clocks = < &clocks 0x5 >;            /* in zephyr/dts/vendor/raspberrypi/rpi_pico/rp2350.dtsi:402 */
			interrupts = < 0xa 0x7 >,
			             < 0xb 0x7 >,
			             < 0xc 0x7 >,
			             < 0xd 0x7 >;            /* in zephyr/dts/vendor/raspberrypi/rpi_pico/rp2350.dtsi:403 */
			interrupt-names = "dma0",
			                  "dma1",
			                  "dma2",
			                  "dma3";            /* in zephyr/dts/vendor/raspberrypi/rpi_pico/rp2350.dtsi:407 */
			dma-channels = < 0x10 >;             /* in zephyr/dts/vendor/raspberrypi/rpi_pico/rp2350.dtsi:408 */
			status = "disabled";                 /* in zephyr/dts/vendor/raspberrypi/rpi_pico/rp2350.dtsi:409 */
			#dma-cells = < 0x3 >;                /* in zephyr/dts/vendor/raspberrypi/rpi_pico/rp2350.dtsi:410 */
		};

		/* node '/soc/usbd@50110000' defined in zephyr/dts/vendor/raspberrypi/rpi_pico/rp2350.dtsi:413 */
		usbd: zephyr_udc0: usbd@50110000 {
			compatible = "raspberrypi,pico-usbd"; /* in zephyr/dts/vendor/raspberrypi/rpi_pico/rp2350.dtsi:414 */
			reg = < 0x50110000 0x10000 >;         /* in zephyr/dts/vendor/raspberrypi/rpi_pico/rp2350.dtsi:415 */
			resets = < &reset 0x1c >;             /* in zephyr/dts/vendor/raspberrypi/rpi_pico/rp2350.dtsi:416 */
			clocks = < &clocks 0x8 >;             /* in zephyr/dts/vendor/raspberrypi/rpi_pico/rp2350.dtsi:417 */
			interrupts = < 0xe 0x7 >;             /* in zephyr/dts/vendor/raspberrypi/rpi_pico/rp2350.dtsi:418 */
			interrupt-names = "usbctrl";          /* in zephyr/dts/vendor/raspberrypi/rpi_pico/rp2350.dtsi:419 */
			num-bidir-endpoints = < 0x10 >;       /* in zephyr/dts/vendor/raspberrypi/rpi_pico/rp2350.dtsi:420 */
			status = "okay";                      /* in zephyr/boards/raspberrypi/rpi_pico2/rpi_pico2.dtsi:117 */
		};

		/* node '/soc/pio@50200000' defined in zephyr/dts/vendor/raspberrypi/rpi_pico/rp2350.dtsi:424 */
		pio0: pio@50200000 {
			compatible = "raspberrypi,pico-pio"; /* in zephyr/dts/vendor/raspberrypi/rpi_pico/rp2350.dtsi:425 */
			reg = < 0x50200000 0x1000 >;         /* in zephyr/dts/vendor/raspberrypi/rpi_pico/rp2350.dtsi:426 */
			clocks = < &clocks 0x5 >;            /* in zephyr/dts/vendor/raspberrypi/rpi_pico/rp2350.dtsi:427 */
			resets = < &reset 0xb >;             /* in zephyr/dts/vendor/raspberrypi/rpi_pico/rp2350.dtsi:428 */
			interrupts = < 0xf 0x7 >,
			             < 0x10 0x7 >;           /* in zephyr/dts/vendor/raspberrypi/rpi_pico/rp2350.dtsi:429 */
			interrupt-names = "irq0",
			                  "irq1";            /* in zephyr/dts/vendor/raspberrypi/rpi_pico/rp2350.dtsi:431 */
			status = "disabled";                 /* in zephyr/dts/vendor/raspberrypi/rpi_pico/rp2350.dtsi:432 */
		};

		/* node '/soc/pio@50300000' defined in zephyr/dts/vendor/raspberrypi/rpi_pico/rp2350.dtsi:435 */
		pio1: pio@50300000 {
			compatible = "raspberrypi,pico-pio"; /* in zephyr/dts/vendor/raspberrypi/rpi_pico/rp2350.dtsi:436 */
			reg = < 0x50300000 0x1000 >;         /* in zephyr/dts/vendor/raspberrypi/rpi_pico/rp2350.dtsi:437 */
			clocks = < &clocks 0x5 >;            /* in zephyr/dts/vendor/raspberrypi/rpi_pico/rp2350.dtsi:438 */
			resets = < &reset 0xc >;             /* in zephyr/dts/vendor/raspberrypi/rpi_pico/rp2350.dtsi:439 */
			interrupts = < 0x11 0x7 >,
			             < 0x12 0x7 >;           /* in zephyr/dts/vendor/raspberrypi/rpi_pico/rp2350.dtsi:440 */
			interrupt-names = "irq0",
			                  "irq1";            /* in zephyr/dts/vendor/raspberrypi/rpi_pico/rp2350.dtsi:442 */
			status = "disabled";                 /* in zephyr/dts/vendor/raspberrypi/rpi_pico/rp2350.dtsi:443 */
		};

		/* node '/soc/pio@50400000' defined in zephyr/dts/vendor/raspberrypi/rpi_pico/rp2350.dtsi:446 */
		pio2: pio@50400000 {
			compatible = "raspberrypi,pico-pio"; /* in zephyr/dts/vendor/raspberrypi/rpi_pico/rp2350.dtsi:447 */
			reg = < 0x50400000 0x1000 >;         /* in zephyr/dts/vendor/raspberrypi/rpi_pico/rp2350.dtsi:448 */
			clocks = < &clocks 0x5 >;            /* in zephyr/dts/vendor/raspberrypi/rpi_pico/rp2350.dtsi:449 */
			resets = < &reset 0xd >;             /* in zephyr/dts/vendor/raspberrypi/rpi_pico/rp2350.dtsi:450 */
			interrupts = < 0x13 0x7 >,
			             < 0x14 0x7 >;           /* in zephyr/dts/vendor/raspberrypi/rpi_pico/rp2350.dtsi:451 */
			interrupt-names = "irq0",
			                  "irq1";            /* in zephyr/dts/vendor/raspberrypi/rpi_pico/rp2350.dtsi:453 */
			status = "disabled";                 /* in zephyr/dts/vendor/raspberrypi/rpi_pico/rp2350.dtsi:454 */
		};

		/* node '/soc/interrupt-controller@e000e100' defined in zephyr/dts/arm/armv8-m.dtsi:13 */
		nvic: interrupt-controller@e000e100 {
			#address-cells = < 0x1 >;            /* in zephyr/dts/arm/armv8-m.dtsi:14 */
			compatible = "arm,v8m-nvic";         /* in zephyr/dts/arm/armv8-m.dtsi:15 */
			reg = < 0xe000e100 0xc00 >;          /* in zephyr/dts/arm/armv8-m.dtsi:16 */
			interrupt-controller;                /* in zephyr/dts/arm/armv8-m.dtsi:17 */
			#interrupt-cells = < 0x2 >;          /* in zephyr/dts/arm/armv8-m.dtsi:18 */
			arm,num-irq-priority-bits = < 0x4 >; /* in zephyr/dts/arm/raspberrypi/rpi_pico/m33.dtsi:21 */
			phandle = < 0x6 >;                   /* in zephyr/dts/arm/armv8-m.dtsi:10 */
		};

		/* node '/soc/timer@e000e010' defined in zephyr/dts/arm/armv8-m.dtsi:21 */
		systick: timer@e000e010 {
			compatible = "arm,armv8m-systick"; /* in zephyr/dts/arm/armv8-m.dtsi:22 */
			reg = < 0xe000e010 0x10 >;         /* in zephyr/dts/arm/armv8-m.dtsi:23 */
		};
	};

	/* node '/pin-controller' defined in zephyr/dts/vendor/raspberrypi/rpi_pico/rp2350.dtsi:458 */
	pinctrl: pin-controller {
		compatible = "raspberrypi,pico-pinctrl"; /* in zephyr/dts/vendor/raspberrypi/rpi_pico/rp2350.dtsi:459 */
		status = "okay";                         /* in zephyr/dts/vendor/raspberrypi/rpi_pico/rp2350.dtsi:460 */

		/* node '/pin-controller/uart0_default' defined in zephyr/boards/raspberrypi/common/rpi_pico-pinctrl-common.dtsi:8 */
		uart0_default: uart0_default {
			phandle = < 0x17 >; /* in zephyr/boards/raspberrypi/rpi_pico2/rpi_pico2.dtsi:68 */

			/* node '/pin-controller/uart0_default/group1' defined in zephyr/boards/raspberrypi/common/rpi_pico-pinctrl-common.dtsi:9 */
			group1 {
				pinmux = < 0x2 >; /* in zephyr/boards/raspberrypi/common/rpi_pico-pinctrl-common.dtsi:10 */
			};

			/* node '/pin-controller/uart0_default/group2' defined in zephyr/boards/raspberrypi/common/rpi_pico-pinctrl-common.dtsi:13 */
			group2 {
				pinmux = < 0x22 >; /* in zephyr/boards/raspberrypi/common/rpi_pico-pinctrl-common.dtsi:14 */
				input-enable;      /* in zephyr/boards/raspberrypi/common/rpi_pico-pinctrl-common.dtsi:15 */
			};
		};

		/* node '/pin-controller/i2c0_default' defined in zephyr/boards/raspberrypi/common/rpi_pico-pinctrl-common.dtsi:19 */
		i2c0_default: i2c0_default {
			phandle = < 0x1a >; /* in ../Documents/BLUELINE/blueline/code_blueline/boards/rpi_pico2_rp2350a_m33.overlay:83 */

			/* node '/pin-controller/i2c0_default/group1' defined in zephyr/boards/raspberrypi/common/rpi_pico-pinctrl-common.dtsi:20 */
			group1 {
				pinmux = < 0x283 >,
				         < 0x2a3 >;   /* in ../Documents/BLUELINE/blueline/code_blueline/boards/rpi_pico2_rp2350a_m33.overlay:7 */
				input-enable;         /* in ../Documents/BLUELINE/blueline/code_blueline/boards/rpi_pico2_rp2350a_m33.overlay:8 */
				input-schmitt-enable; /* in ../Documents/BLUELINE/blueline/code_blueline/boards/rpi_pico2_rp2350a_m33.overlay:9 */
			};
		};

		/* node '/pin-controller/i2c1_default' defined in zephyr/boards/raspberrypi/common/rpi_pico-pinctrl-common.dtsi:27 */
		i2c1_default: i2c1_default {
			phandle = < 0x1b >; /* in ../Documents/BLUELINE/blueline/code_blueline/boards/rpi_pico2_rp2350a_m33.overlay:54 */

			/* node '/pin-controller/i2c1_default/group1' defined in zephyr/boards/raspberrypi/common/rpi_pico-pinctrl-common.dtsi:28 */
			group1 {
				pinmux = < 0x143 >,
				         < 0x163 >;   /* in ../Documents/BLUELINE/blueline/code_blueline/boards/rpi_pico2_rp2350a_m33.overlay:15 */
				input-enable;         /* in ../Documents/BLUELINE/blueline/code_blueline/boards/rpi_pico2_rp2350a_m33.overlay:16 */
				input-schmitt-enable; /* in ../Documents/BLUELINE/blueline/code_blueline/boards/rpi_pico2_rp2350a_m33.overlay:17 */
			};
		};

		/* node '/pin-controller/spi0_default' defined in zephyr/boards/raspberrypi/common/rpi_pico-pinctrl-common.dtsi:35 */
		spi0_default: spi0_default {
			phandle = < 0x19 >; /* in ../Documents/BLUELINE/blueline/code_blueline/boards/rpi_pico2_rp2350a_m33.overlay:118 */

			/* node '/pin-controller/spi0_default/group1' defined in zephyr/boards/raspberrypi/common/rpi_pico-pinctrl-common.dtsi:36 */
			group1 {
				pinmux = < 0x241 >,
				         < 0x261 >; /* in ../Documents/BLUELINE/blueline/code_blueline/boards/rpi_pico2_rp2350a_m33.overlay:23 */
			};

			/* node '/pin-controller/spi0_default/group2' defined in zephyr/boards/raspberrypi/common/rpi_pico-pinctrl-common.dtsi:40 */
			group2 {
				pinmux = < 0x201 >; /* in ../Documents/BLUELINE/blueline/code_blueline/boards/rpi_pico2_rp2350a_m33.overlay:26 */
				input-enable;       /* in ../Documents/BLUELINE/blueline/code_blueline/boards/rpi_pico2_rp2350a_m33.overlay:27 */
			};
		};

		/* node '/pin-controller/pwm_ch4b_default' defined in zephyr/boards/raspberrypi/common/rpi_pico-pinctrl-common.dtsi:46 */
		pwm_ch4b_default: pwm_ch4b_default {
			phandle = < 0x1d >; /* in zephyr/boards/raspberrypi/rpi_pico2/rpi_pico2.dtsi:103 */

			/* node '/pin-controller/pwm_ch4b_default/group1' defined in zephyr/boards/raspberrypi/common/rpi_pico-pinctrl-common.dtsi:47 */
			group1 {
				pinmux = < 0x324 >; /* in zephyr/boards/raspberrypi/common/rpi_pico-pinctrl-common.dtsi:48 */
			};
		};

		/* node '/pin-controller/adc_default' defined in zephyr/boards/raspberrypi/common/rpi_pico-pinctrl-common.dtsi:52 */
		adc_default: adc_default {
			phandle = < 0x1c >; /* in zephyr/boards/raspberrypi/rpi_pico2/rpi_pico2.dtsi:97 */

			/* node '/pin-controller/adc_default/group1' defined in zephyr/boards/raspberrypi/common/rpi_pico-pinctrl-common.dtsi:53 */
			group1 {
				pinmux = < 0x35f >,
				         < 0x37f >,
				         < 0x39f >,
				         < 0x3bf >; /* in zephyr/boards/raspberrypi/common/rpi_pico-pinctrl-common.dtsi:54 */
				input-enable;       /* in zephyr/boards/raspberrypi/common/rpi_pico-pinctrl-common.dtsi:55 */
			};
		};

		/* node '/pin-controller/uart1_default' defined in ../Documents/BLUELINE/blueline/code_blueline/boards/rpi_pico2_rp2350a_m33.overlay:31 */
		uart1_default: uart1_default {
			phandle = < 0x18 >; /* in ../Documents/BLUELINE/blueline/code_blueline/boards/rpi_pico2_rp2350a_m33.overlay:48 */

			/* node '/pin-controller/uart1_default/group1' defined in ../Documents/BLUELINE/blueline/code_blueline/boards/rpi_pico2_rp2350a_m33.overlay:32 */
			group1 {
				pinmux = < 0x82 >; /* in ../Documents/BLUELINE/blueline/code_blueline/boards/rpi_pico2_rp2350a_m33.overlay:33 */
			};

			/* node '/pin-controller/uart1_default/group2' defined in ../Documents/BLUELINE/blueline/code_blueline/boards/rpi_pico2_rp2350a_m33.overlay:35 */
			group2 {
				pinmux = < 0xa2 >;    /* in ../Documents/BLUELINE/blueline/code_blueline/boards/rpi_pico2_rp2350a_m33.overlay:36 */
				input-enable;         /* in ../Documents/BLUELINE/blueline/code_blueline/boards/rpi_pico2_rp2350a_m33.overlay:37 */
				input-schmitt-enable; /* in ../Documents/BLUELINE/blueline/code_blueline/boards/rpi_pico2_rp2350a_m33.overlay:38 */
			};
		};
	};

	/* node '/dietemp' defined in zephyr/dts/vendor/raspberrypi/rpi_pico/rp2350.dtsi:463 */
	die_temp: dietemp {
		compatible = "raspberrypi,pico-temp"; /* in zephyr/dts/vendor/raspberrypi/rpi_pico/rp2350.dtsi:464 */
		status = "disabled";                  /* in zephyr/dts/vendor/raspberrypi/rpi_pico/rp2350.dtsi:465 */
		io-channels = < &adc 0x4 >;           /* in zephyr/dts/vendor/raspberrypi/rpi_pico/rp2350a.dtsi:8 */
	};

	/* node '/chosen' defined in zephyr/dts/common/skeleton.dtsi:13 */
	chosen {
		zephyr,sram = &sram0;           /* in zephyr/boards/raspberrypi/rpi_pico2/rpi_pico2.dtsi:16 */
		zephyr,flash = &flash0;         /* in zephyr/boards/raspberrypi/rpi_pico2/rpi_pico2.dtsi:17 */
		zephyr,flash-controller = &qmi; /* in zephyr/boards/raspberrypi/rpi_pico2/rpi_pico2.dtsi:18 */
		zephyr,console = &uart0;        /* in zephyr/boards/raspberrypi/rpi_pico2/rpi_pico2.dtsi:19 */
		zephyr,shell-uart = &uart0;     /* in zephyr/boards/raspberrypi/rpi_pico2/rpi_pico2.dtsi:20 */
	};

	/* node '/connector' defined in zephyr/boards/raspberrypi/rpi_pico2/rpi_pico2.dtsi:27 */
	pico_header: connector {
		compatible = "raspberrypi,pico-header";    /* in zephyr/boards/raspberrypi/rpi_pico2/rpi_pico2.dtsi:28 */
		#gpio-cells = < 0x2 >;                     /* in zephyr/boards/raspberrypi/rpi_pico2/rpi_pico2.dtsi:29 */
		gpio-map-mask = < 0xffffffff 0xffffffc0 >; /* in zephyr/boards/raspberrypi/rpi_pico2/rpi_pico2.dtsi:30 */
		gpio-map-pass-thru = < 0x0 0x3f >;         /* in zephyr/boards/raspberrypi/rpi_pico2/rpi_pico2.dtsi:31 */
		gpio-map = < 0x0 0x0 &gpio0 0x0 0x0 >,
		           < 0x1 0x0 &gpio0 0x1 0x0 >,
		           < 0x2 0x0 &gpio0 0x2 0x0 >,
		           < 0x3 0x0 &gpio0 0x3 0x0 >,
		           < 0x4 0x0 &gpio0 0x4 0x0 >,
		           < 0x5 0x0 &gpio0 0x5 0x0 >,
		           < 0x6 0x0 &gpio0 0x6 0x0 >,
		           < 0x7 0x0 &gpio0 0x7 0x0 >,
		           < 0x8 0x0 &gpio0 0x8 0x0 >,
		           < 0x9 0x0 &gpio0 0x9 0x0 >,
		           < 0xa 0x0 &gpio0 0xa 0x0 >,
		           < 0xb 0x0 &gpio0 0xb 0x0 >,
		           < 0xc 0x0 &gpio0 0xc 0x0 >,
		           < 0xd 0x0 &gpio0 0xd 0x0 >,
		           < 0xe 0x0 &gpio0 0xe 0x0 >,
		           < 0xf 0x0 &gpio0 0xf 0x0 >,
		           < 0x10 0x0 &gpio0 0x10 0x0 >,
		           < 0x11 0x0 &gpio0 0x11 0x0 >,
		           < 0x12 0x0 &gpio0 0x12 0x0 >,
		           < 0x13 0x0 &gpio0 0x13 0x0 >,
		           < 0x14 0x0 &gpio0 0x14 0x0 >,
		           < 0x15 0x0 &gpio0 0x15 0x0 >,
		           < 0x16 0x0 &gpio0 0x16 0x0 >,
		           < 0x1a 0x0 &gpio0 0x1a 0x0 >,
		           < 0x1b 0x0 &gpio0 0x1b 0x0 >,
		           < 0x1c 0x0 &gpio0 0x1c 0x0 >;   /* in zephyr/boards/raspberrypi/rpi_pico2/rpi_pico2.dtsi:32 */
	};

	/* node '/leds' defined in zephyr/boards/raspberrypi/common/rpi_pico-led.dtsi:9 */
	leds {
		compatible = "gpio-leds"; /* in zephyr/boards/raspberrypi/common/rpi_pico-led.dtsi:10 */

		/* node '/leds/led_0' defined in zephyr/boards/raspberrypi/common/rpi_pico-led.dtsi:12 */
		led0: led_0 {
			gpios = < &gpio0 0x19 0x0 >; /* in zephyr/boards/raspberrypi/common/rpi_pico-led.dtsi:13 */
			label = "LED";               /* in zephyr/boards/raspberrypi/common/rpi_pico-led.dtsi:14 */
		};
	};

	/* node '/pwm_leds' defined in zephyr/boards/raspberrypi/common/rpi_pico-led.dtsi:18 */
	pwm_leds {
		compatible = "pwm-leds"; /* in zephyr/boards/raspberrypi/common/rpi_pico-led.dtsi:19 */
		status = "disabled";     /* in zephyr/boards/raspberrypi/common/rpi_pico-led.dtsi:20 */

		/* node '/pwm_leds/pwm_led_0' defined in zephyr/boards/raspberrypi/common/rpi_pico-led.dtsi:22 */
		pwm_led0: pwm_led_0 {
			pwms = < &pwm 0x9 0x1312d00 0x0 >; /* in zephyr/boards/raspberrypi/common/rpi_pico-led.dtsi:23 */
			label = "PWM_LED";                 /* in zephyr/boards/raspberrypi/common/rpi_pico-led.dtsi:24 */
		};
	};

	/* node '/hooksw' defined in ../Documents/BLUELINE/blueline/code_blueline/boards/rpi_pico2_rp2350a_m33.overlay:130 */
	hooksw {
		compatible = "gpio-leds"; /* in ../Documents/BLUELINE/blueline/code_blueline/boards/rpi_pico2_rp2350a_m33.overlay:131 */

		/* node '/hooksw/rstn' defined in ../Documents/BLUELINE/blueline/code_blueline/boards/rpi_pico2_rp2350a_m33.overlay:132 */
		rst_n: rstn {
			gpios = < &gpio0 0x6 0x0 >; /* in ../Documents/BLUELINE/blueline/code_blueline/boards/rpi_pico2_rp2350a_m33.overlay:133 */
		};
	};

	/* node '/dled_0' defined in ../Documents/BLUELINE/blueline/code_blueline/boards/rpi_pico2_rp2350a_m33.overlay:138 */
	dled_0 {
		compatible = "gpio-leds"; /* in ../Documents/BLUELINE/blueline/code_blueline/boards/rpi_pico2_rp2350a_m33.overlay:139 */

		/* node '/dled_0/dled_0' defined in ../Documents/BLUELINE/blueline/code_blueline/boards/rpi_pico2_rp2350a_m33.overlay:140 */
		dled0: dled_0 {
			gpios = < &gpio0 0xe 0x0 >; /* in ../Documents/BLUELINE/blueline/code_blueline/boards/rpi_pico2_rp2350a_m33.overlay:141 */
		};
	};

	/* node '/dled_1' defined in ../Documents/BLUELINE/blueline/code_blueline/boards/rpi_pico2_rp2350a_m33.overlay:145 */
	dled_1 {
		compatible = "gpio-leds"; /* in ../Documents/BLUELINE/blueline/code_blueline/boards/rpi_pico2_rp2350a_m33.overlay:146 */

		/* node '/dled_1/dled_1' defined in ../Documents/BLUELINE/blueline/code_blueline/boards/rpi_pico2_rp2350a_m33.overlay:147 */
		dled1: dled_1 {
			gpios = < &gpio0 0x19 0x0 >; /* in ../Documents/BLUELINE/blueline/code_blueline/boards/rpi_pico2_rp2350a_m33.overlay:148 */
		};
	};

	/* node '/button_0' defined in ../Documents/BLUELINE/blueline/code_blueline/boards/rpi_pico2_rp2350a_m33.overlay:154 */
	button_0 {
		compatible = "gpio-keys"; /* in ../Documents/BLUELINE/blueline/code_blueline/boards/rpi_pico2_rp2350a_m33.overlay:155 */

		/* node '/button_0/button_0' defined in ../Documents/BLUELINE/blueline/code_blueline/boards/rpi_pico2_rp2350a_m33.overlay:156 */
		button0: button_0 {
			gpios = < &gpio0 0x3 0x1 >; /* in ../Documents/BLUELINE/blueline/code_blueline/boards/rpi_pico2_rp2350a_m33.overlay:157 */
		};
	};

	/* node '/button_1' defined in ../Documents/BLUELINE/blueline/code_blueline/boards/rpi_pico2_rp2350a_m33.overlay:161 */
	button_1 {
		compatible = "gpio-keys"; /* in ../Documents/BLUELINE/blueline/code_blueline/boards/rpi_pico2_rp2350a_m33.overlay:162 */

		/* node '/button_1/button_1' defined in ../Documents/BLUELINE/blueline/code_blueline/boards/rpi_pico2_rp2350a_m33.overlay:163 */
		button1: button_1 {
			gpios = < &gpio0 0x16 0x1 >; /* in ../Documents/BLUELINE/blueline/code_blueline/boards/rpi_pico2_rp2350a_m33.overlay:164 */
		};
	};

	/* node '/button_2' defined in ../Documents/BLUELINE/blueline/code_blueline/boards/rpi_pico2_rp2350a_m33.overlay:168 */
	button_2 {
		compatible = "gpio-keys"; /* in ../Documents/BLUELINE/blueline/code_blueline/boards/rpi_pico2_rp2350a_m33.overlay:169 */

		/* node '/button_2/button_2' defined in ../Documents/BLUELINE/blueline/code_blueline/boards/rpi_pico2_rp2350a_m33.overlay:170 */
		button2: button_2 {
			gpios = < &gpio0 0xf 0x11 >; /* in ../Documents/BLUELINE/blueline/code_blueline/boards/rpi_pico2_rp2350a_m33.overlay:171 */
		};
	};

	/* node '/det_int' defined in ../Documents/BLUELINE/blueline/code_blueline/boards/rpi_pico2_rp2350a_m33.overlay:175 */
	det_int {
		compatible = "gpio-keys"; /* in ../Documents/BLUELINE/blueline/code_blueline/boards/rpi_pico2_rp2350a_m33.overlay:176 */

		/* node '/det_int/det_int' defined in ../Documents/BLUELINE/blueline/code_blueline/boards/rpi_pico2_rp2350a_m33.overlay:177 */
		detint: det_int {
			gpios = < &gpio0 0x9 0x1 >; /* in ../Documents/BLUELINE/blueline/code_blueline/boards/rpi_pico2_rp2350a_m33.overlay:178 */
		};
	};
};
